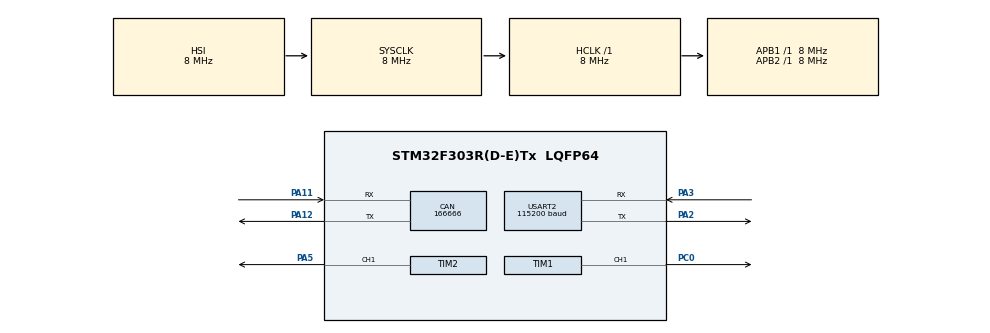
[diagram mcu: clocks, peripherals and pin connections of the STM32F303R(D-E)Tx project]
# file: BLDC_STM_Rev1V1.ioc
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CAN.CalculateBaudRate=166666
CAN.CalculateTimeBit=6000
CAN.CalculateTimeQuantum=2000.0
Mcu.Family=STM32F3
Mcu.Name=STM32F303R(D-E)Tx
Mcu.Package=LQFP64
NVIC.PriorityGroup=NVIC_PRIORITYGROUP_4
PA11.GPIO_PuPd=GPIO_PULLUP
PA11.Mode=CAN_Activate
PA11.Signal=CAN_RX
PA12.GPIO_PuPd=GPIO_PULLUP
PA12.Mode=CAN_Activate
PA12.Signal=CAN_TX
PA13.Mode=Serial_Wire
PA13.Signal=SYS_JTMS-SWDIO
PA14.Mode=Serial_Wire
PA14.Signal=SYS_JTCK-SWCLK
PA2.Mode=Asynchronous
PA2.Signal=USART2_TX
PA3.Mode=Asynchronous
PA3.Signal=USART2_RX
PA5.Signal=S_TIM2_CH1_ETR
PC0.Signal=S_TIM1_CH1
ProjectManager.HeapSize=0x200
ProjectManager.StackSize=0x400
ProjectManager.TargetToolchain=STM32CubeIDE
RCC.AHBFreq_Value=8000000
RCC.APB1Freq_Value=8000000
RCC.APB2Freq_Value=8000000
RCC.CortexFreq_Value=8000000
RCC.HSE_VALUE=8000000
RCC.HSI_VALUE=8000000
RCC.LSE_VALUE=32768
RCC.SYSCLKFreq_VALUE=8000000
RCC.USBFreq_Value=16000000
SH.S_TIM1_CH1.0=TIM1_CH1,PWM Generation1 CH1
SH.S_TIM2_CH1_ETR.0=TIM2_CH1,PWM Generation1 CH1
TIM1.Channel-PWM\ Generation1\ CH1=TIM_CHANNEL_1
TIM1.Period=625
TIM1.Prescaler=127
TIM2.Channel-PWM\ Generation1\ CH1=TIM_CHANNEL_1
TIM2.Period=1000
TIM2.Prescaler=840-1
USART2.BaudRate=115200
USART2.Parity=PARITY_EVEN
USART2.VirtualMode-Asynchronous=VM_ASYNC
VP_TIM2_VS_ClockSourceINT.Mode=Internal
board=custom

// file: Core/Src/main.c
/* USER CODE BEGIN Header */
/**
  ******************************************************************************
  * @file           : main.c
  * @brief          : Main program body
  ******************************************************************************
  * @attention
  *
  * Copyright (c) 2024 STMicroelectronics.
  * All rights reserved.
  *
  * This software is licensed under terms that can be found in the LICENSE file
  * in the root directory of this software component.
  * If no LICENSE file comes with this software, it is provided AS-IS.
  *
  ******************************************************************************
  */
/* USER CODE END Header */
#include "main.h"

CAN_HandleTypeDef hcan;

TIM_HandleTypeDef htim1;
TIM_HandleTypeDef htim2;

UART_HandleTypeDef huart2;

/* USER CODE BEGIN PV */

uint8_t rxBuffer; // Buffer to hold received bytes

/* USER CODE END PV */

void SystemClock_Config(void);
static void MX_GPIO_Init(void);
static void MX_TIM1_Init(void);
static void MX_USART2_UART_Init(void);
static void MX_TIM2_Init(void);
static void MX_CAN_Init(void);

/* USER CODE BEGIN 0 */
uint16_t pulse_value = 0;
uint8_t fade_direction = 1;
/* USER CODE END 0 */

int main(void)
{

  /* MCU Configuration--------------------------------------------------------*/

  /* Reset of all peripherals, Initializes the Flash interface and the Systick. */
  HAL_Init();

  /* Configure the system clock */
  SystemClock_Config();

  /* Initialize all configured peripherals */
  MX_GPIO_Init();
  MX_TIM1_Init();
  MX_USART2_UART_Init();
  MX_TIM2_Init();
  MX_CAN_Init();
  /* USER CODE BEGIN 2 */
  //HAL_TIM_PWM_Start(&htim1, TIM_CHANNEL_1); // Starts PWM timer
  HAL_TIM_PWM_Start(&htim2, TIM_CHANNEL_1);

  /* USER CODE END 2 */

  /* Infinite loop */
  /* USER CODE BEGIN WHILE */
  while (1)
  {
	  __HAL_RCC_CAN1_CLK_ENABLE();
	  // LED
//	  HAL_GPIO_TogglePin(GPIOA, GPIO_1_Pin);
//	  HAL_Delay(50);

	  // Timer
//	  __HAL_TIM_SET_COMPARE(&htim2, TIM_CHANNEL_1, pulse_value);  // Set duty cycle
//
//	     if (fade_direction)  // Increase brightness
//	     {
//	         pulse_value += 10;
//	         if (pulse_value >= 1000) fade_direction = 0;  // Start decreasing
//	     }
//	     else  // Decrease brightness
//	     {
//	         pulse_value -= 10;
//	         if (pulse_value == 0) fade_direction = 1;  // Start increasing
//	     }
//
//	     HAL_Delay(10);  // Small delay for smooth fading effect

	  // UART
//	  if (HAL_UART_Transmit(&huart2, "TEST ", 6, 100) != HAL_OK)
//	  	  Error_Handler();
//
//	  HAL_Delay(500);

//	  // UART
//	  if (__HAL_UART_GET_FLAG(&huart2, UART_FLAG_RXNE) == SET) {
//		  if (HAL_UART_Receive(&huart2, &rxBuffer, 1, HAL_MAX_DELAY) == HAL_OK) {
//			  	  HAL_UART_Receive(&huart2, rxBuffer, 16, 100);
//			  } else {
//				  Error_Handler();
//			  }
//	  }

    /* USER CODE END WHILE */

  }
}

void SystemClock_Config(void)
{
  RCC_OscInitTypeDef RCC_OscInitStruct = {0};
  RCC_ClkInitTypeDef RCC_ClkInitStruct = {0};
  RCC_PeriphCLKInitTypeDef PeriphClkInit = {0};

  /** Initializes the RCC Oscillators according to the specified parameters
  * in the RCC_OscInitTypeDef structure.
  */
  RCC_OscInitStruct.OscillatorType = RCC_OSCILLATORTYPE_HSI;
  RCC_OscInitStruct.HSIState = RCC_HSI_ON;
  RCC_OscInitStruct.HSICalibrationValue = RCC_HSICALIBRATION_DEFAULT;
  RCC_OscInitStruct.PLL.PLLState = RCC_PLL_NONE;
  if (HAL_RCC_OscConfig(&RCC_OscInitStruct) != HAL_OK)
  {
    Error_Handler();
  }

  /** Initializes the CPU, AHB and APB buses clocks
  */
  RCC_ClkInitStruct.ClockType = RCC_CLOCKTYPE_HCLK|RCC_CLOCKTYPE_SYSCLK
                              |RCC_CLOCKTYPE_PCLK1|RCC_CLOCKTYPE_PCLK2;
  RCC_ClkInitStruct.SYSCLKSource = RCC_SYSCLKSOURCE_HSI;
  RCC_ClkInitStruct.AHBCLKDivider = RCC_SYSCLK_DIV1;
  RCC_ClkInitStruct.APB1CLKDivider = RCC_HCLK_DIV1;
  RCC_ClkInitStruct.APB2CLKDivider = RCC_HCLK_DIV1;

  if (HAL_RCC_ClockConfig(&RCC_ClkInitStruct, FLASH_LATENCY_0) != HAL_OK)
  {
    Error_Handler();
  }
  PeriphClkInit.PeriphClockSelection = RCC_PERIPHCLK_USART2|RCC_PERIPHCLK_TIM1
                              |RCC_PERIPHCLK_TIM2;
  PeriphClkInit.Usart2ClockSelection = RCC_USART2CLKSOURCE_PCLK1;
  PeriphClkInit.Tim1ClockSelection = RCC_TIM1CLK_HCLK;
  PeriphClkInit.Tim2ClockSelection = RCC_TIM2CLK_HCLK;
  if (HAL_RCCEx_PeriphCLKConfig(&PeriphClkInit) != HAL_OK)
  {
    Error_Handler();
  }
}

static void MX_CAN_Init(void)
{

  hcan.Instance = CAN;
  hcan.Init.Prescaler = 16;
  hcan.Init.Mode = CAN_MODE_NORMAL;
  hcan.Init.SyncJumpWidth = CAN_SJW_1TQ;
  hcan.Init.TimeSeg1 = CAN_BS1_1TQ;
  hcan.Init.TimeSeg2 = CAN_BS2_1TQ;
  hcan.Init.TimeTriggeredMode = DISABLE;
  hcan.Init.AutoBusOff = DISABLE;
  hcan.Init.AutoWakeUp = DISABLE;
  hcan.Init.AutoRetransmission = DISABLE;
  hcan.Init.ReceiveFifoLocked = DISABLE;
  hcan.Init.TransmitFifoPriority = DISABLE;
  if (HAL_CAN_Init(&hcan) != HAL_OK)
  {
    Error_Handler();
  }

}

static void MX_TIM1_Init(void)
{

  TIM_MasterConfigTypeDef sMasterConfig = {0};
  TIM_OC_InitTypeDef sConfigOC = {0};
  TIM_BreakDeadTimeConfigTypeDef sBreakDeadTimeConfig = {0};

  htim1.Instance = TIM1;
  htim1.Init.Prescaler = 127;
  htim1.Init.CounterMode = TIM_COUNTERMODE_UP;
  htim1.Init.Period = 625;
  htim1.Init.ClockDivision = TIM_CLOCKDIVISION_DIV1;
  htim1.Init.RepetitionCounter = 0;
  htim1.Init.AutoReloadPreload = TIM_AUTORELOAD_PRELOAD_DISABLE;
  if (HAL_TIM_PWM_Init(&htim1) != HAL_OK)
  {
    Error_Handler();
  }
  sMasterConfig.MasterOutputTrigger = TIM_TRGO_RESET;
  sMasterConfig.MasterOutputTrigger2 = TIM_TRGO2_RESET;
  sMasterConfig.MasterSlaveMode = TIM_MASTERSLAVEMODE_DISABLE;
  if (HAL_TIMEx_MasterConfigSynchronization(&htim1, &sMasterConfig) != HAL_OK)
  {
    Error_Handler();
  }
  sConfigOC.OCMode = TIM_OCMODE_PWM1;
  sConfigOC.Pulse = 0;
  sConfigOC.OCPolarity = TIM_OCPOLARITY_HIGH;
  sConfigOC.OCNPolarity = TIM_OCNPOLARITY_HIGH;
  sConfigOC.OCFastMode = TIM_OCFAST_DISABLE;
  sConfigOC.OCIdleState = TIM_OCIDLESTATE_RESET;
  sConfigOC.OCNIdleState = TIM_OCNIDLESTATE_RESET;
  if (HAL_TIM_PWM_ConfigChannel(&htim1, &sConfigOC, TIM_CHANNEL_1) != HAL_OK)
  {
    Error_Handler();
  }
  sBreakDeadTimeConfig.OffStateRunMode = TIM_OSSR_DISABLE;
  sBreakDeadTimeConfig.OffStateIDLEMode = TIM_OSSI_DISABLE;
  sBreakDeadTimeConfig.LockLevel = TIM_LOCKLEVEL_OFF;
  sBreakDeadTimeConfig.DeadTime = 0;
  sBreakDeadTimeConfig.BreakState = TIM_BREAK_DISABLE;
  sBreakDeadTimeConfig.BreakPolarity = TIM_BREAKPOLARITY_HIGH;
  sBreakDeadTimeConfig.BreakFilter = 0;
  sBreakDeadTimeConfig.Break2State = TIM_BREAK2_DISABLE;
  sBreakDeadTimeConfig.Break2Polarity = TIM_BREAK2POLARITY_HIGH;
  sBreakDeadTimeConfig.Break2Filter = 0;
  sBreakDeadTimeConfig.AutomaticOutput = TIM_AUTOMATICOUTPUT_DISABLE;
  if (HAL_TIMEx_ConfigBreakDeadTime(&htim1, &sBreakDeadTimeConfig) != HAL_OK)
  {
    Error_Handler();
  }
  HAL_TIM_MspPostInit(&htim1);

}

static void MX_TIM2_Init(void)
{

  TIM_ClockConfigTypeDef sClockSourceConfig = {0};
  TIM_MasterConfigTypeDef sMasterConfig = {0};
  TIM_OC_InitTypeDef sConfigOC = {0};

  htim2.Instance = TIM2;
  htim2.Init.Prescaler = 840-1;
  htim2.Init.CounterMode = TIM_COUNTERMODE_UP;
  htim2.Init.Period = 1000;
  htim2.Init.ClockDivision = TIM_CLOCKDIVISION_DIV1;
  htim2.Init.AutoReloadPreload = TIM_AUTORELOAD_PRELOAD_DISABLE;
  if (HAL_TIM_Base_Init(&htim2) != HAL_OK)
  {
    Error_Handler();
  }
  sClockSourceConfig.ClockSource = TIM_CLOCKSOURCE_INTERNAL;
  if (HAL_TIM_ConfigClockSource(&htim2, &sClockSourceConfig) != HAL_OK)
  {
    Error_Handler();
  }
  if (HAL_TIM_PWM_Init(&htim2) != HAL_OK)
  {
    Error_Handler();
  }
  sMasterConfig.MasterOutputTrigger = TIM_TRGO_RESET;
  sMasterConfig.MasterSlaveMode = TIM_MASTERSLAVEMODE_DISABLE;
  if (HAL_TIMEx_MasterConfigSynchronization(&htim2, &sMasterConfig) != HAL_OK)
  {
    Error_Handler();
  }
  sConfigOC.OCMode = TIM_OCMODE_PWM1;
  sConfigOC.Pulse = 0;
  sConfigOC.OCPolarity = TIM_OCPOLARITY_HIGH;
  sConfigOC.OCFastMode = TIM_OCFAST_DISABLE;
  if (HAL_TIM_PWM_ConfigChannel(&htim2, &sConfigOC, TIM_CHANNEL_1) != HAL_OK)
  {
    Error_Handler();
  }
  HAL_TIM_MspPostInit(&htim2);

}

static void MX_USART2_UART_Init(void)
{

  huart2.Instance = USART2;
  huart2.Init.BaudRate = 115200;
  huart2.Init.WordLength = UART_WORDLENGTH_8B;
  huart2.Init.StopBits = UART_STOPBITS_1;
  huart2.Init.Parity = UART_PARITY_EVEN;
  huart2.Init.Mode = UART_MODE_TX_RX;
  huart2.Init.HwFlowCtl = UART_HWCONTROL_NONE;
  huart2.Init.OverSampling = UART_OVERSAMPLING_16;
  huart2.Init.OneBitSampling = UART_ONE_BIT_SAMPLE_DISABLE;
  huart2.AdvancedInit.AdvFeatureInit = UART_ADVFEATURE_NO_INIT;
  if (HAL_UART_Init(&huart2) != HAL_OK)
  {
    Error_Handler();
  }

}

static void MX_GPIO_Init(void)
{

  /* GPIO Ports Clock Enable */
  __HAL_RCC_GPIOC_CLK_ENABLE();
  __HAL_RCC_GPIOA_CLK_ENABLE();

}

void Error_Handler(void)
{
  __disable_irq();
  while (1)
  {
  }
}
